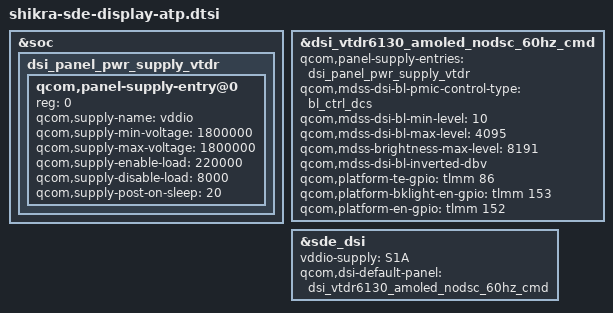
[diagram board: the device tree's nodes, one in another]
// SPDX-License-Identifier: BSD-3-Clause
/*
 * Copyright (c) Qualcomm Technologies, Inc. and/or its subsidiaries.
 */

#include "shikra-sde-display.dtsi"

&soc {
	dsi_panel_pwr_supply_vtdr: dsi_panel_pwr_supply_vtdr {
		#address-cells = <1>;
		#size-cells = <0>;

		qcom,panel-supply-entry@0 {
			reg = <0>;
			qcom,supply-name = "vddio";
			qcom,supply-min-voltage = <1800000>;
			qcom,supply-max-voltage = <1800000>;
			qcom,supply-enable-load = <220000>;
			qcom,supply-disable-load = <8000>;
			qcom,supply-post-on-sleep = <20>;
		};
	};
};


&dsi_vtdr6130_amoled_nodsc_60hz_cmd {
	qcom,panel-supply-entries = <&dsi_panel_pwr_supply_vtdr>;
	qcom,mdss-dsi-bl-pmic-control-type = "bl_ctrl_dcs";
	qcom,mdss-dsi-bl-min-level = <10>;
	qcom,mdss-dsi-bl-max-level = <4095>;
	qcom,mdss-brightness-max-level = <8191>;
	qcom,mdss-dsi-bl-inverted-dbv;
	qcom,platform-te-gpio = <&tlmm 86 0>;
	qcom,platform-bklight-en-gpio = <&tlmm 153 0>;
	qcom,platform-en-gpio = <&tlmm 152 0>;
};

&sde_dsi {
	vddio-supply = <&S1A>;
	qcom,dsi-default-panel = <&dsi_vtdr6130_amoled_nodsc_60hz_cmd>;
};
